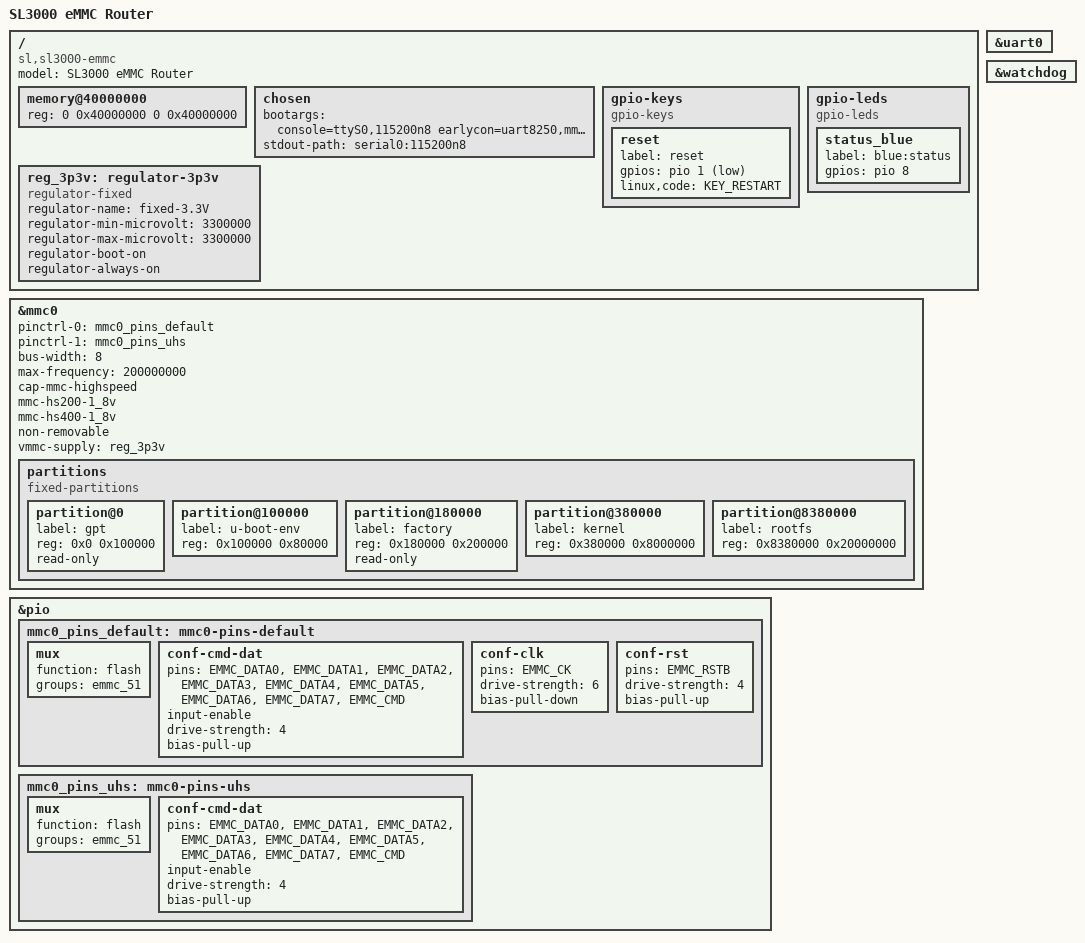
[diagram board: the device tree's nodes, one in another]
// SPDX-License-Identifier: (GPL-2.0 OR MIT)
/dts-v1/;

#include <dt-bindings/gpio/gpio.h>
#include <dt-bindings/input/input.h>
#include <dt-bindings/leds/common.h>
#include "mt7981.dtsi"

/ {
    model = "SL3000 eMMC Router";
    compatible = "sl,sl3000-emmc", "mediatek,mt7981";

    memory@40000000 {
        device_type = "memory";
        reg = <0 0x40000000 0 0x40000000>;
    };

    chosen {
        bootargs = "console=ttyS0,115200n8 earlycon=uart8250,mmio32,0x11002000";
        stdout-path = "serial0:115200n8";
    };

    gpio-keys {
        compatible = "gpio-keys";

        reset {
            label = "reset";
            gpios = <&pio 1 GPIO_ACTIVE_LOW>;
            linux,code = <KEY_RESTART>;
        };
    };

    gpio-leds {
        compatible = "gpio-leds";

        status_blue {
            label = "blue:status";
            gpios = <&pio 8 GPIO_ACTIVE_HIGH>;
        };
    };

    reg_3p3v: regulator-3p3v {
        compatible = "regulator-fixed";
        regulator-name = "fixed-3.3V";
        regulator-min-microvolt = <3300000>;
        regulator-max-microvolt = <3300000>;
        regulator-boot-on;
        regulator-always-on;
    };
};

&uart0 {
    status = "okay";
};

&mmc0 {
    pinctrl-names = "default", "state_uhs";
    pinctrl-0 = <&mmc0_pins_default>;
    pinctrl-1 = <&mmc0_pins_uhs>;
    bus-width = <8>;
    max-frequency = <200000000>;
    cap-mmc-highspeed;
    mmc-hs200-1_8v;
    mmc-hs400-1_8v;
    non-removable;
    vmmc-supply = <&reg_3p3v>;
    status = "okay";

    partitions {
        compatible = "fixed-partitions";
        #address-cells = <1>;
        #size-cells = <1>;

        partition@0 {
            label = "gpt";
            reg = <0x0 0x100000>;
            read-only;
        };

        partition@100000 {
            label = "u-boot-env";
            reg = <0x100000 0x80000>;
        };

        partition@180000 {
            label = "factory";
            reg = <0x180000 0x200000>;
            read-only;
        };

        partition@380000 {
            label = "kernel";
            reg = <0x380000 0x8000000>;
        };

        partition@8380000 {
            label = "rootfs";
            reg = <0x8380000 0x20000000>;
        };
    };
};

&pio {
    mmc0_pins_default: mmc0-pins-default {
        mux {
            function = "flash";
            groups = "emmc_51";
        };

        conf-cmd-dat {
            pins = "EMMC_DATA0", "EMMC_DATA1", "EMMC_DATA2", "EMMC_DATA3",
                   "EMMC_DATA4", "EMMC_DATA5", "EMMC_DATA6", "EMMC_DATA7", "EMMC_CMD";
            input-enable;
            drive-strength = <4>;
            bias-pull-up;
        };

        conf-clk {
            pins = "EMMC_CK";
            drive-strength = <6>;
            bias-pull-down;
        };

        conf-rst {
            pins = "EMMC_RSTB";
            drive-strength = <4>;
            bias-pull-up;
        };
    };

    mmc0_pins_uhs: mmc0-pins-uhs {
        mux {
            function = "flash";
            groups = "emmc_51";
        };

        conf-cmd-dat {
            pins = "EMMC_DATA0", "EMMC_DATA1", "EMMC_DATA2", "EMMC_DATA3",
                   "EMMC_DATA4", "EMMC_DATA5", "EMMC_DATA6", "EMMC_DATA7", "EMMC_CMD";
            input-enable;
            drive-strength = <4>;
            bias-pull-up;
        };
    };
};

&watchdog {
    status = "okay";
};
